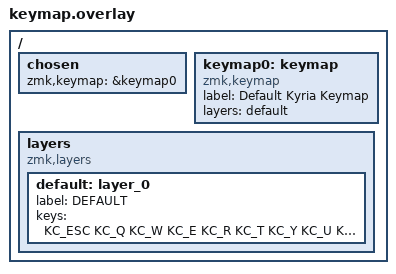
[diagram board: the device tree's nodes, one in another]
#include <behaviors.dtsi>
#include <dt-bindings/zmk/keys.h>
#include <dt-bindings/zmk/matrix-transform.h>
#include <keymap.h>

/ {
	chosen {
		zmk,keymap = &keymap0;
	};
	
	keymap0: keymap {
		compatible = "zmk,keymap";
		label ="Default Kyria Keymap";
		layers = <&default>;
	};

	layers {
		compatible = "zmk,layers";

		default: layer_0 {
			label = "DEFAULT";
// ---------------------------------------------------------------------------------------------------------------------------------
// |  ESC  |  Q  |  W  |  E   |  R   |  T   |                                          |  Y   |  U    |  I    |  O   |   P   | "|" |
// |  <-   |  A  |  S  |  D   |  F   |  G   |                                          |  H   |  J    |  K    |  L   |   ;   |  '  |
// | SHIFT |  Z  |  X  |  C   |  V   |  B   | L SHIFT | L SHIFT |  | L SHIFT | L SHIFT |  N   |  M    |  ,    |  .   |   /   |  -  |
//                     | GUI  | DEL  | RET  |  SPACE  |   ESC   |  |   RET   |  SPACE  | TAB  | BSPC  | R-ALT |
			keys = <
	KC_ESC  KC_Q   KC_W KC_E    KC_R   KC_T                                             KC_Y   KC_U    KC_I    KC_O   KC_P    KC_PIPE
	KC_BKSP KC_A   KC_S KC_D    KC_F   KC_G                                             KC_H   KC_J    KC_K    KC_L   KC_SCLN KC_QUOT
	KC_LSFT KC_Z   KC_X KC_C    KC_V   KC_B    KC_LSFT KC_LSFT      KC_LSFT   KC_LSFT   KC_N   KC_M    KC_CMMA KC_DOT KC_BSLH KC_MIN
	                    KC_LGUI KC_DEL KC_RET  KC_SPC  KC_ESC       KC_RET    KC_SPC    KC_TAB KC_BKSP KC_RALT
	>;
		};
	};
};
